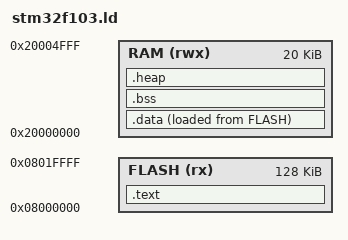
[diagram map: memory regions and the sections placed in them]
MEMORY
{
    FLASH (rx)  : ORIGIN = 0x08000000, LENGTH = 128K
    RAM   (rwx) : ORIGIN = 0x20000000, LENGTH = 20K
}

SECTIONS
{
    .text :
    {
        . = ALIGN(4);
        KEEP(*(.isr_vector))
        *(.text)
        *(.text*)
        *(.rodata)
        *(.rodata*)
        . = ALIGN(4);
    } > FLASH

    .data :
    {
        . = ALIGN(4);
        _sdata = .;
        *(.data)
        *(.data*)
        . = ALIGN(4);
        _edata = .;
    } > RAM AT > FLASH

    .bss :
    {
        . = ALIGN(4);
        __bss_start__ = .;
        _sbss = .;
        *(.bss)
        *(.bss*)
        *(COMMON)
        . = ALIGN(4);
        _ebss = .;
        __bss_end__ = .;
    } > RAM

    .heap :
    {
        . = ALIGN(4);
        _end = .;
        end = .;
        . = . + 1024; /* Cấp dung lượng heap tối thiểu */
    } > RAM
}
